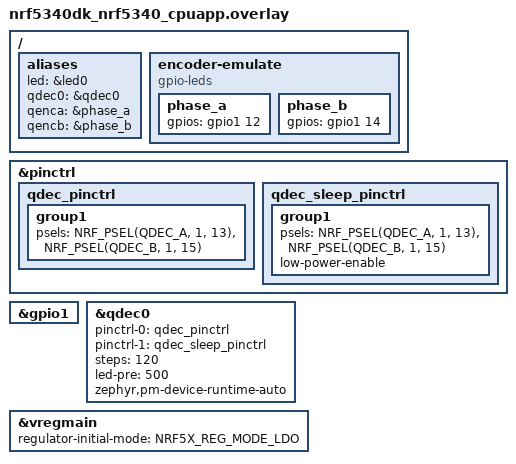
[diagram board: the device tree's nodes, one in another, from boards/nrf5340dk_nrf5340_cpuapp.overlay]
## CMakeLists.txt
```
#
# Copyright (c) 2024 Nordic Semiconductor ASA
#
# SPDX-License-Identifier: LicenseRef-Nordic-5-Clause
#

cmake_minimum_required(VERSION 3.20.0)

find_package(Zephyr REQUIRED HINTS $ENV{ZEPHYR_BASE})

if(NOT SYSBUILD)
  message(FATAL_ERROR
    " This is a multi-image application that should be built using sysbuild.\n"
    " Add --sysbuild argument to west build command to prepare all the images."
  )
endif()

project(qdec)

target_sources(app PRIVATE src/main.c)
```

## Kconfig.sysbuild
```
#
# Copyright (c) 2023 Nordic Semiconductor ASA
#
# SPDX-License-Identifier: LicenseRef-Nordic-5-Clause
#

config REMOTE_BOARD
	string
	default "$(BOARD)/nrf54h20/cpurad" if SOC_NRF54H20_CPUAPP

source "share/sysbuild/Kconfig"
```

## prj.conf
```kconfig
CONFIG_SENSOR=y

# Enable runtime power management for peripheral
CONFIG_PM_DEVICE=y
CONFIG_PM_DEVICE_RUNTIME=y

CONFIG_CONSOLE=n
CONFIG_UART_CONSOLE=n
CONFIG_SERIAL=n
CONFIG_BOOT_BANNER=n
CONFIG_NCS_BOOT_BANNER=n

CONFIG_ASSERT=y
```

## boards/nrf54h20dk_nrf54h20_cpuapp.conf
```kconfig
CONFIG_PM=y
CONFIG_POWEROFF=y

CONFIG_SOC_NRF54H20_CPURAD_ENABLE=y
```

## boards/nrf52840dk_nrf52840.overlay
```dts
/*
 * Copyright 2025 Nordic Semiconductor ASA
 * SPDX-License-Identifier: LicenseRef-Nordic-5-Clause
 */

/*
 * Two loopbacks are required:
 * P1.01 - P1.02
 * P1.03 - P1.04
 */

/ {
	aliases {
		led = &led0;
		qdec0 = &qdec0;
		qenca = &phase_a;
		qencb = &phase_b;
	};

	encoder-emulate {
		compatible = "gpio-leds";
		phase_a: phase_a {
			gpios = <&gpio1 12 GPIO_ACTIVE_HIGH>;
		};
		phase_b: phase_b {
			gpios = <&gpio1 14 GPIO_ACTIVE_HIGH>;
		};
	};
};

&pinctrl {
	qdec_pinctrl: qdec_pinctrl {
		group1 {
			psels = <NRF_PSEL(QDEC_A, 1, 13)>,
				<NRF_PSEL(QDEC_B, 1, 15)>;
		};
	};
	qdec_sleep_pinctrl: qdec_sleep_pinctrl {
		group1 {
			psels = <NRF_PSEL(QDEC_A, 1, 13)>,
				<NRF_PSEL(QDEC_B, 1, 15)>;
			low-power-enable;
		};
	};
};

&gpio1 {
	status = "okay";
};

&qdec0 {
	status = "okay";
	pinctrl-0 = <&qdec_pinctrl>;
	pinctrl-1 = <&qdec_sleep_pinctrl>;
	pinctrl-names = "default", "sleep";
	steps = <120>;
	led-pre = <500>;
	zephyr,pm-device-runtime-auto;
};
```

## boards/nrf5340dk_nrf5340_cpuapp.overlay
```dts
/*
 * Copyright 2025 Nordic Semiconductor ASA
 * SPDX-License-Identifier: LicenseRef-Nordic-5-Clause
 */

/*
 * Two loopbacks are required:
 * P0.04 - P0.05
 * P0.06 - P0.07
 */

/ {
	aliases {
		led = &led0;
		qdec0 = &qdec0;
		qenca = &phase_a;
		qencb = &phase_b;
	};

	encoder-emulate {
		compatible = "gpio-leds";

		phase_a: phase_a {
			gpios = <&gpio1 12 GPIO_ACTIVE_HIGH>;
		};

		phase_b: phase_b {
			gpios = <&gpio1 14 GPIO_ACTIVE_HIGH>;
		};
	};
};

&pinctrl {
	qdec_pinctrl: qdec_pinctrl {
		group1 {
			psels = <NRF_PSEL(QDEC_A, 1, 13)>,
				<NRF_PSEL(QDEC_B, 1, 15)>;
		};
	};

	qdec_sleep_pinctrl: qdec_sleep_pinctrl {
		group1 {
			psels = <NRF_PSEL(QDEC_A, 1, 13)>,
				<NRF_PSEL(QDEC_B, 1, 15)>;
			low-power-enable;
		};
	};
};

&gpio1 {
	status = "okay";
};

&qdec0 {
	status = "okay";
	pinctrl-0 = <&qdec_pinctrl>;
	pinctrl-1 = <&qdec_sleep_pinctrl>;
	pinctrl-names = "default", "sleep";
	steps = <120>;
	led-pre = <500>;
	zephyr,pm-device-runtime-auto;
};

&vregmain {
	regulator-initial-mode = <NRF5X_REG_MODE_LDO>;
};
```

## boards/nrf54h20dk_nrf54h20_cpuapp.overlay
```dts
/*
 * Copyright 2024 Nordic Semiconductor ASA
 * SPDX-License-Identifier: LicenseRef-Nordic-5-Clause
 */

/ {
	aliases {
		led = &led0;
		/delete-property/ led1;
		qdec0 = &qdec130;
		qenca = &phase_a;
		qencb = &phase_b;
	};

	encoder-emulate {
		compatible = "gpio-leds";

		phase_a: phase_a {
			gpios = <&gpio2 9 GPIO_ACTIVE_HIGH>;
		};

		phase_b: phase_b {
			gpios = <&gpio2 11 GPIO_ACTIVE_HIGH>;
		};
	};
};

/delete-node/ &led1;

&pinctrl {
	qdec_pinctrl: qdec_pinctrl {
		group1 {
			psels = <NRF_PSEL(QDEC_A, 2, 8)>,
				<NRF_PSEL(QDEC_B, 2, 10)>;
		};
	};

	qdec_sleep_pinctrl: qdec_sleep_pinctrl {
		group1 {
			psels = <NRF_PSEL(QDEC_A, 2, 8)>,
				<NRF_PSEL(QDEC_B, 2, 10)>;
			low-power-enable;
		};
	};
};

&gpio2 {
	status = "okay";
	zephyr,pm-device-runtime-auto;
};

&qdec130 {
	status = "okay";
	pinctrl-0 = <&qdec_pinctrl>;
	pinctrl-1 = <&qdec_sleep_pinctrl>;
	pinctrl-names = "default", "sleep";
	steps = <127>;
	led-pre = <500>;
	zephyr,pm-device-runtime-auto;
};

/* To prevent enabling console receiver. */
&uart136 {
	disable-rx;
};
```

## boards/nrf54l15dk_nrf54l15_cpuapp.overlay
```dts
/*
 * Copyright 2024 Nordic Semiconductor ASA
 * SPDX-License-Identifier: LicenseRef-Nordic-5-Clause
 */

/ {
	aliases {
		led = &button3;
		qdec0 = &qdec20;
		qenca = &phase_a;
		qencb = &phase_b;
	};

	encoder-emulate {
		compatible = "gpio-leds";

		phase_a: phase_a {
			gpios = <&gpio1 9 GPIO_ACTIVE_HIGH>;
		};

		phase_b: phase_b {
			gpios = <&gpio1 11 GPIO_ACTIVE_HIGH>;
		};
	};
};

&pinctrl {
	qdec_pinctrl: qdec_pinctrl {
		group1 {
			psels = <NRF_PSEL(QDEC_A, 1, 8)>,
				<NRF_PSEL(QDEC_B, 1, 10)>;
		};
	};

	qdec_sleep_pinctrl: qdec_sleep_pinctrl {
		group1 {
			psels = <NRF_PSEL(QDEC_A, 1, 8)>,
				<NRF_PSEL(QDEC_B, 1, 10)>;
			low-power-enable;
		};
	};
};

&gpio1 {
	status = "okay";
};

&qdec20 {
	status = "okay";
	pinctrl-0 = <&qdec_pinctrl>;
	pinctrl-1 = <&qdec_sleep_pinctrl>;
	pinctrl-names = "default", "sleep";
	steps = <127>;
	led-pre = <500>;
	zephyr,pm-device-runtime-auto;
};
```

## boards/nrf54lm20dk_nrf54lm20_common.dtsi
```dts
/*
 * Copyright 2026 Nordic Semiconductor ASA
 * SPDX-License-Identifier: LicenseRef-Nordic-5-Clause
 */

/*
 * Two loopbacks are required:
 * P1.13 - P1.14
 * P1.23 - P1.24
 */

/ {
	aliases {
		led = &led0;
		/delete-property/ led1;
		qdec0 = &qdec20;
		qenca = &phase_a;
		qencb = &phase_b;
	};

	encoder-emulate {
		compatible = "gpio-leds";

		phase_a: phase_a {
			gpios = <&gpio1 13 GPIO_ACTIVE_HIGH>;
		};

		phase_b: phase_b {
			gpios = <&gpio1 23 GPIO_ACTIVE_HIGH>;
		};
	};
};

/delete-node/ &led1;

&pinctrl {
	qdec_pinctrl: qdec_pinctrl {
		group1 {
			psels = <NRF_PSEL(QDEC_A, 1, 14)>,
				<NRF_PSEL(QDEC_B, 1, 24)>;
		};
	};

	qdec_sleep_pinctrl: qdec_sleep_pinctrl {
		group1 {
			psels = <NRF_PSEL(QDEC_A, 1, 14)>,
				<NRF_PSEL(QDEC_B, 1, 24)>;
			low-power-enable;
		};
	};
};

&gpio1 {
	status = "okay";
};

&qdec20 {
	status = "okay";
	pinctrl-0 = <&qdec_pinctrl>;
	pinctrl-1 = <&qdec_sleep_pinctrl>;
	pinctrl-names = "default", "sleep";
	steps = <120>;
	led-pre = <500>;
	zephyr,pm-device-runtime-auto;
};
```

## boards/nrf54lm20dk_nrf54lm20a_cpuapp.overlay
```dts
/*
 * Copyright 2024 Nordic Semiconductor ASA
 * SPDX-License-Identifier: LicenseRef-Nordic-5-Clause
 */

/*
 * Two loopbacks are required:
 * P1.13 - P1.14
 * P1.23 - P1.24
 */

/ {
	aliases {
		led = &led0;
		/delete-property/ led1;
		qdec0 = &qdec20;
		qenca = &phase_a;
		qencb = &phase_b;
	};

	encoder-emulate {
		compatible = "gpio-leds";

		phase_a: phase_a {
			gpios = <&gpio1 13 GPIO_ACTIVE_HIGH>;
		};

		phase_b: phase_b {
			gpios = <&gpio1 23 GPIO_ACTIVE_HIGH>;
		};
	};
};

/delete-node/ &led1;

&pinctrl {
	qdec_pinctrl: qdec_pinctrl {
		group1 {
			psels = <NRF_PSEL(QDEC_A, 1, 14)>,
				<NRF_PSEL(QDEC_B, 1, 24)>;
		};
	};

	qdec_sleep_pinctrl: qdec_sleep_pinctrl {
		group1 {
			psels = <NRF_PSEL(QDEC_A, 1, 14)>,
				<NRF_PSEL(QDEC_B, 1, 24)>;
			low-power-enable;
		};
	};
};

&gpio1 {
	status = "okay";
};

&qdec20 {
	status = "okay";
	pinctrl-0 = <&qdec_pinctrl>;
	pinctrl-1 = <&qdec_sleep_pinctrl>;
	pinctrl-names = "default", "sleep";
	steps = <120>;
	led-pre = <500>;
	zephyr,pm-device-runtime-auto;
};
```

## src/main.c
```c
/*
 * Copyright (c) 2024 Nordic Semiconductor ASA
 *
 * SPDX-License-Identifier: LicenseRef-Nordic-5-Clause
 */
#include <zephyr/kernel.h>
#include <zephyr/device.h>
#include <zephyr/drivers/sensor.h>
#include <zephyr/drivers/gpio.h>
#include <zephyr/pm/device_runtime.h>


#define LOG_LEVEL LOG_LEVEL_DBG

#define QDEC DT_ALIAS(qdec0)

extern struct k_sem semaphore;

const struct gpio_dt_spec led = GPIO_DT_SPEC_GET(DT_ALIAS(led0), gpios);

static const struct gpio_dt_spec phase_a = GPIO_DT_SPEC_GET(DT_ALIAS(qenca), gpios);
static const struct gpio_dt_spec phase_b = GPIO_DT_SPEC_GET(DT_ALIAS(qencb), gpios);
static const struct device *const qdec_dev = DEVICE_DT_GET(DT_ALIAS(qdec0));
static const uint32_t qdec_config_step = DT_PROP(DT_ALIAS(qdec0), steps);
static bool toggle_a = true;

static void qenc_emulate_work_handler(struct k_work *work)
{
	if (toggle_a) {
		gpio_pin_toggle_dt(&phase_a);
	} else {
		gpio_pin_toggle_dt(&phase_b);
	}
	toggle_a = !toggle_a;
}

static K_WORK_DEFINE(qenc_emulate_work, qenc_emulate_work_handler);

static void qenc_emulate_timer_handler(struct k_timer *dummy)
{
	k_work_submit(&qenc_emulate_work);
}

static K_TIMER_DEFINE(qenc_emulate_timer, qenc_emulate_timer_handler, NULL);

static void qenc_emulate_start(k_timeout_t period, bool forward)
{
	gpio_pin_set_dt(&phase_a, 0);
	gpio_pin_set_dt(&phase_b, 0);

	toggle_a = !forward;

	k_timer_start(&qenc_emulate_timer, period, period);
}

static void qenc_emulate_stop(void)
{
	k_timer_stop(&qenc_emulate_timer);

	gpio_pin_set_dt(&phase_a, 0);
	gpio_pin_set_dt(&phase_b, 0);
}

static void qenc_emulate_verify_reading(int emulator_period_ms, int emulation_duration_ms,
					bool forward)
{
	int rc;
	struct sensor_value val = {0};
	int32_t expected_steps = emulation_duration_ms / emulator_period_ms;
	int32_t expected_reading = 360 * expected_steps / qdec_config_step;
	int32_t delta = expected_reading / 5;

	if (!forward) {
		expected_reading *= -1;
	}

	qenc_emulate_start(K_MSEC(emulator_period_ms), forward);
	k_msleep(emulation_duration_ms);
	qenc_emulate_stop();

	rc = sensor_sample_fetch(qdec_dev);
	__ASSERT_NO_MSG(rc == 0);

	rc = sensor_channel_get(qdec_dev, SENSOR_CHAN_ROTATION, &val);
	__ASSERT_NO_MSG(rc == 0);

	rc = ((val.val1 >= (expected_reading + delta)) || (val.val1 <= (expected_reading - delta)))
		     ? 1
		     : 0;
	__ASSERT_NO_MSG(rc == 0);

	/* wait and get readings to clear state */
	k_msleep(20);
	rc = sensor_sample_fetch(qdec_dev);
	__ASSERT_NO_MSG(rc == 0);

	rc = sensor_channel_get(qdec_dev, SENSOR_CHAN_ROTATION, &val);
	__ASSERT_NO_MSG(rc == 0);
}

void init_device(void)
{
	int rc;

	rc = device_is_ready(qdec_dev);
	__ASSERT_NO_MSG(rc);

	rc = gpio_is_ready_dt(&phase_a);
	__ASSERT_NO_MSG(rc);

	rc = gpio_pin_configure_dt(&phase_a, GPIO_OUTPUT);
	__ASSERT_NO_MSG(rc == 0);

	rc = gpio_is_ready_dt(&phase_b);
	__ASSERT_NO_MSG(rc);

	rc = gpio_pin_configure_dt(&phase_b, GPIO_OUTPUT);
	__ASSERT_NO_MSG(rc == 0);
}

int main(void)
{
	int rc;

	rc = gpio_is_ready_dt(&led);
	__ASSERT(rc, "Error: GPIO Device not ready");

	rc = gpio_pin_configure_dt(&led, GPIO_OUTPUT_ACTIVE);
	__ASSERT(rc == 0, "Could not configure led GPIO");

	init_device();

	while (1) {
		if (IS_ENABLED(CONFIG_PM_DEVICE_RUNTIME)) {
			rc = pm_device_runtime_get(qdec_dev);
			__ASSERT_NO_MSG(rc == 0);
		}
		qenc_emulate_verify_reading(20, 450, true);
		qenc_emulate_verify_reading(20, 450, false);
		if (IS_ENABLED(CONFIG_PM_DEVICE_RUNTIME)) {
			rc = pm_device_runtime_put(qdec_dev);
			__ASSERT_NO_MSG(rc == 0);
		}
		gpio_pin_set_dt(&led, 0);
		k_msleep(1000);
		gpio_pin_set_dt(&led, 1);
	}
	return 0;
}
```
